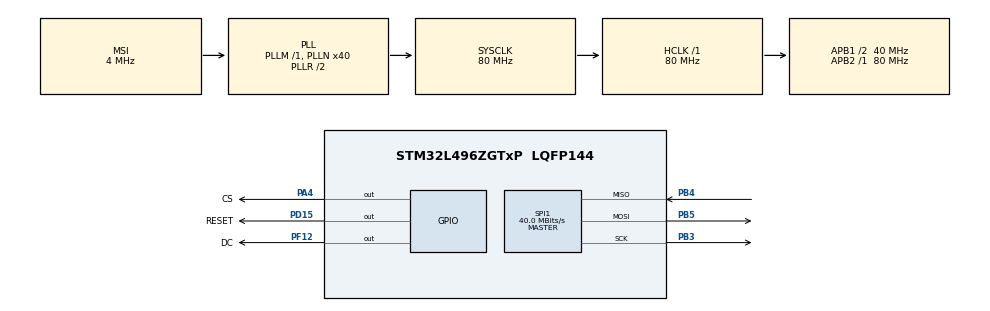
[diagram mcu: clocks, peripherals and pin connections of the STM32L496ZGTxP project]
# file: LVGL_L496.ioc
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Dma.Request0=SPI1_TX
Dma.SPI1_TX.0.Direction=DMA_MEMORY_TO_PERIPH
Dma.SPI1_TX.0.Instance=DMA1_Channel3
Dma.SPI1_TX.0.MemDataAlignment=DMA_MDATAALIGN_BYTE
Dma.SPI1_TX.0.MemInc=DMA_MINC_ENABLE
Dma.SPI1_TX.0.Mode=DMA_NORMAL
Dma.SPI1_TX.0.PeriphDataAlignment=DMA_PDATAALIGN_BYTE
Dma.SPI1_TX.0.PeriphInc=DMA_PINC_DISABLE
Dma.SPI1_TX.0.Priority=DMA_PRIORITY_LOW
Mcu.Family=STM32L4
Mcu.Name=STM32L496ZGTxP
Mcu.Package=LQFP144
NVIC.DMA1_Channel3_IRQn=true\:0\:0\:false\:false\:true\:false\:true\:true
NVIC.PriorityGroup=NVIC_PRIORITYGROUP_4
NVIC.SPI1_IRQn=true\:0\:0\:false\:false\:true\:true\:true\:true
PA13\ (JTMS/SWDIO).Mode=Serial_Wire
PA13\ (JTMS/SWDIO).Signal=SYS_JTMS-SWDIO
PA14\ (JTCK/SWCLK).Mode=Serial_Wire
PA14\ (JTCK/SWCLK).Signal=SYS_JTCK-SWCLK
PA4.GPIO_Label=CS
PA4.Signal=GPIO_Output
PB3\ (JTDO/TRACESWO).Mode=Full_Duplex_Master
PB3\ (JTDO/TRACESWO).Signal=SPI1_SCK
PB4\ (NJTRST).Mode=Full_Duplex_Master
PB4\ (NJTRST).Signal=SPI1_MISO
PB5.Mode=Full_Duplex_Master
PB5.Signal=SPI1_MOSI
PC14-OSC32_IN\ (PC14).Mode=LSE-External-Oscillator
PC14-OSC32_IN\ (PC14).Signal=RCC_OSC32_IN
PC15-OSC32_OUT\ (PC15).Mode=LSE-External-Oscillator
PC15-OSC32_OUT\ (PC15).Signal=RCC_OSC32_OUT
PD15.GPIO_Label=RESET
PD15.Signal=GPIO_Output
PF12.GPIO_Label=DC
PF12.Signal=GPIO_Output
ProjectManager.HeapSize=0x200
ProjectManager.StackSize=0x400
ProjectManager.TargetToolchain=STM32CubeIDE
RCC.48MHZClocksFreq_Value=24000000
RCC.ADCFreq_Value=40000000
RCC.AHBFreq_Value=80000000
RCC.APB1CLKDivider=RCC_HCLK_DIV2
RCC.APB1Freq_Value=40000000
RCC.APB1TimFreq_Value=80000000
RCC.APB2Freq_Value=80000000
RCC.APB2TimFreq_Value=80000000
RCC.CortexFreq_Value=80000000
RCC.HCLKFreq_Value=80000000
RCC.HSE_VALUE=8000000
RCC.HSI48_VALUE=48000000
RCC.HSI_VALUE=16000000
RCC.MSI_VALUE=4000000
RCC.PLLMUL=RCC_PLL_MUL9
RCC.PLLN=40
RCC.PLLSAI1N=20
RCC.PRESCALERUSB=RCC_USBCLKSOURCE_PLL_DIV1_5
RCC.SYSCLKFreq_VALUE=80000000
RCC.SYSCLKSource=RCC_SYSCLKSOURCE_PLLCLK
RCC.SYSCLKSourceVirtual=RCC_SYSCLKSOURCE_PLLCLK
RCC.USBFreq_Value=40000000
RCC.VCOOutputFreq_Value=160000000
SPI1.CalculateBaudRate=40.0 MBits/s
SPI1.DataSize=SPI_DATASIZE_8BIT
SPI1.Direction=SPI_DIRECTION_2LINES
SPI1.Mode=SPI_MODE_MASTER
SPI1.VirtualType=VM_MASTER
board=NUCLEO-L496ZG-P

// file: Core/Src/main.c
/* USER CODE BEGIN Header */
/**
  ******************************************************************************
  * @file           : main.c
  * @brief          : Main program body
  ******************************************************************************
  * @attention
  *
  * Copyright (c) 2025 STMicroelectronics.
  * All rights reserved.
  *
  * This software is licensed under terms that can be found in the LICENSE file
  * in the root directory of this software component.
  * If no LICENSE file comes with this software, it is provided AS-IS.
  *
  ******************************************************************************
  */
/* USER CODE END Header */
#include "main.h"

/* USER CODE BEGIN Includes */
#include "lvgl.h"
#include "LCDController.h"
#include "ui_welcome.h"
/* USER CODE END Includes */

SPI_HandleTypeDef hspi1;
DMA_HandleTypeDef hdma_spi1_tx;

void SystemClock_Config(void);
static void MX_GPIO_Init(void);
static void MX_DMA_Init(void);
static void MX_SPI1_Init(void);

int main(void)
{

  /* MCU Configuration--------------------------------------------------------*/

  /* Reset of all peripherals, Initializes the Flash interface and the Systick. */
  HAL_Init();

  /* Configure the system clock */
  SystemClock_Config();

  /* Initialize all configured peripherals */
  MX_GPIO_Init();
  MX_DMA_Init();
  MX_SPI1_Init();
  /* USER CODE BEGIN 2 */
  lv_init();

  lv_port_disp_init();

  ui_welcome_screen_init();

  /* USER CODE END 2 */

  /* Infinite loop */
  while (1)
  {

    /* USER CODE BEGIN 3 */
    lv_timer_handler();
    HAL_Delay(5);
  }
  /* USER CODE END 3 */
}

void SystemClock_Config(void)
{
  RCC_OscInitTypeDef RCC_OscInitStruct = {0};
  RCC_ClkInitTypeDef RCC_ClkInitStruct = {0};

  /** Configure the main internal regulator output voltage
  */
  if (HAL_PWREx_ControlVoltageScaling(PWR_REGULATOR_VOLTAGE_SCALE1) != HAL_OK)
  {
    Error_Handler();
  }

  /** Initializes the RCC Oscillators according to the specified parameters
  * in the RCC_OscInitTypeDef structure.
  */
  RCC_OscInitStruct.OscillatorType = RCC_OSCILLATORTYPE_MSI;
  RCC_OscInitStruct.MSIState = RCC_MSI_ON;
  RCC_OscInitStruct.MSICalibrationValue = 0;
  RCC_OscInitStruct.MSIClockRange = RCC_MSIRANGE_6;
  RCC_OscInitStruct.PLL.PLLState = RCC_PLL_ON;
  RCC_OscInitStruct.PLL.PLLSource = RCC_PLLSOURCE_MSI;
  RCC_OscInitStruct.PLL.PLLM = 1;
  RCC_OscInitStruct.PLL.PLLN = 40;
  RCC_OscInitStruct.PLL.PLLP = RCC_PLLP_DIV2;
  RCC_OscInitStruct.PLL.PLLQ = RCC_PLLQ_DIV2;
  RCC_OscInitStruct.PLL.PLLR = RCC_PLLR_DIV2;
  if (HAL_RCC_OscConfig(&RCC_OscInitStruct) != HAL_OK)
  {
    Error_Handler();
  }

  /** Initializes the CPU, AHB and APB buses clocks
  */
  RCC_ClkInitStruct.ClockType = RCC_CLOCKTYPE_HCLK|RCC_CLOCKTYPE_SYSCLK
                              |RCC_CLOCKTYPE_PCLK1|RCC_CLOCKTYPE_PCLK2;
  RCC_ClkInitStruct.SYSCLKSource = RCC_SYSCLKSOURCE_PLLCLK;
  RCC_ClkInitStruct.AHBCLKDivider = RCC_SYSCLK_DIV1;
  RCC_ClkInitStruct.APB1CLKDivider = RCC_HCLK_DIV2;
  RCC_ClkInitStruct.APB2CLKDivider = RCC_HCLK_DIV1;

  if (HAL_RCC_ClockConfig(&RCC_ClkInitStruct, FLASH_LATENCY_4) != HAL_OK)
  {
    Error_Handler();
  }
}

static void MX_SPI1_Init(void)
{

  /* SPI1 parameter configuration*/
  hspi1.Instance = SPI1;
  hspi1.Init.Mode = SPI_MODE_MASTER;
  hspi1.Init.Direction = SPI_DIRECTION_2LINES;
  hspi1.Init.DataSize = SPI_DATASIZE_8BIT;
  hspi1.Init.CLKPolarity = SPI_POLARITY_LOW;
  hspi1.Init.CLKPhase = SPI_PHASE_1EDGE;
  hspi1.Init.NSS = SPI_NSS_SOFT;
  hspi1.Init.BaudRatePrescaler = SPI_BAUDRATEPRESCALER_2;
  hspi1.Init.FirstBit = SPI_FIRSTBIT_MSB;
  hspi1.Init.TIMode = SPI_TIMODE_DISABLE;
  hspi1.Init.CRCCalculation = SPI_CRCCALCULATION_DISABLE;
  hspi1.Init.CRCPolynomial = 7;
  hspi1.Init.CRCLength = SPI_CRC_LENGTH_DATASIZE;
  hspi1.Init.NSSPMode = SPI_NSS_PULSE_ENABLE;
  if (HAL_SPI_Init(&hspi1) != HAL_OK)
  {
    Error_Handler();
  }

}

static void MX_DMA_Init(void)
{

  /* DMA controller clock enable */
  __HAL_RCC_DMA1_CLK_ENABLE();

  /* DMA interrupt init */
  /* DMA1_Channel3_IRQn interrupt configuration */
  HAL_NVIC_SetPriority(DMA1_Channel3_IRQn, 0, 0);
  HAL_NVIC_EnableIRQ(DMA1_Channel3_IRQn);

}

static void MX_GPIO_Init(void)
{
  GPIO_InitTypeDef GPIO_InitStruct = {0};

  /* GPIO Ports Clock Enable */
  __HAL_RCC_GPIOC_CLK_ENABLE();
  __HAL_RCC_GPIOA_CLK_ENABLE();
  __HAL_RCC_GPIOF_CLK_ENABLE();
  __HAL_RCC_GPIOD_CLK_ENABLE();
  __HAL_RCC_GPIOB_CLK_ENABLE();

  /*Configure GPIO pin Output Level */
  HAL_GPIO_WritePin(CS_GPIO_Port, CS_Pin, GPIO_PIN_RESET);

  /*Configure GPIO pin Output Level */
  HAL_GPIO_WritePin(DC_GPIO_Port, DC_Pin, GPIO_PIN_RESET);

  /*Configure GPIO pin : CS_Pin */
  GPIO_InitStruct.Pin = CS_Pin;
  GPIO_InitStruct.Mode = GPIO_MODE_OUTPUT_PP;
  GPIO_InitStruct.Pull = GPIO_NOPULL;
  GPIO_InitStruct.Speed = GPIO_SPEED_FREQ_LOW;
  HAL_GPIO_Init(CS_GPIO_Port, &GPIO_InitStruct);

  /*Configure GPIO pin : DC_Pin */
  GPIO_InitStruct.Pin = DC_Pin;
  GPIO_InitStruct.Mode = GPIO_MODE_OUTPUT_PP;
  GPIO_InitStruct.Pull = GPIO_NOPULL;
  GPIO_InitStruct.Speed = GPIO_SPEED_FREQ_LOW;
  HAL_GPIO_Init(DC_GPIO_Port, &GPIO_InitStruct);

  /*Configure GPIO pin : RESET_Pin */
  GPIO_InitStruct.Pin = RESET_Pin;
  GPIO_InitStruct.Mode = GPIO_MODE_OUTPUT_PP; // CORRECTION : Output Push Pull
  GPIO_InitStruct.Pull = GPIO_NOPULL;
  GPIO_InitStruct.Speed = GPIO_SPEED_FREQ_LOW;
  HAL_GPIO_Init(RESET_GPIO_Port, &GPIO_InitStruct);

  // AJOUT CONSEILLÉ : Mettre le RESET à l'état HAUT par défaut pour démarrer
  HAL_GPIO_WritePin(RESET_GPIO_Port, RESET_Pin, GPIO_PIN_SET);

}

void Error_Handler(void)
{
  __disable_irq();
  while (1)
  {
  }
}
